# ATSAMA5D27CLD1G register map
Vendor: Microchip Technology; Series: SAMA5D2; File version: 0
Registers are 32-bit, read-write, reset 0x0 unless marked. A register's access mark holds for its fields unless they carry their own. Offsets are from the block's base; [hi:lo] are bit positions; {n}, {i} and the like mark numbered series.

## SFC — Secure Fuse Controller
Base 0xF804C000; register names take the prefix SFC_
0x00 KR wo — SFC Key Register
  [7:0] KEY — Key Code
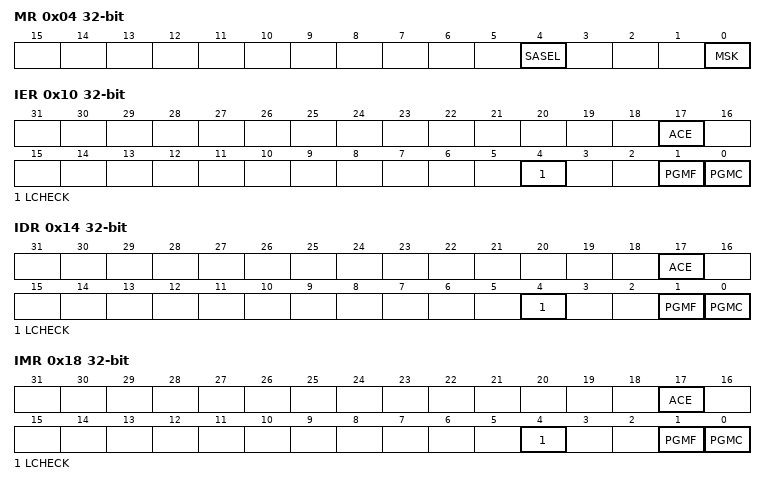
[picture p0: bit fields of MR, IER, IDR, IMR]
0x04 MR — SFC Mode Register
  [4] SASEL — Sense Amplifier Selection
  [0] MSK — Mask Data Registers
0x10 IER wo — SFC Interrupt Enable Register
  [17] ACE — Area Check Error Interrupt Enable
  [4] LCHECK — Live Integrity Check Error Interrupt Enable
  [1] PGMF — Programming Sequence Failed Interrupt Enable
  [0] PGMC — Programming Sequence Completed Interrupt Enable
0x14 IDR wo — SFC Interrupt Disable Register
  [17] ACE — Area Check Error Interrupt Disable
  [4] LCHECK — Live Integrity Check Error Interrupt Disable
  [1] PGMF — Programming Sequence Failed Interrupt Disable
  [0] PGMC — Programming Sequence Completed Interrupt Disable
0x18 IMR ro — SFC Interrupt Mask Register
  [17] ACE — Area Check Error Interrupt Mask
  [4] LCHECK — Live Integrity Checking Error Interrupt Mask
  [1] PGMF — Programming Sequence Failed Interrupt Mask
  [0] PGMC — Programming Sequence Completed Interrupt Mask
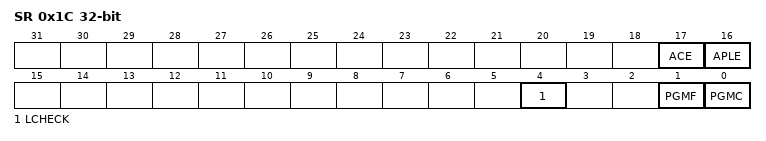
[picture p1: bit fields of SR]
0x1C SR ro — SFC Status Register
  [17] ACE — Area Check Error (cleared on read)
  [16] APLE — Area Programming Lock Error (cleared on read)
  [4] LCHECK — Live Integrity Checking Error (cleared on read)
  [1] PGMF — Programming Sequence Failed (cleared on read)
  [0] PGMC — Programming Sequence Completed (cleared on read)
{0x20+4i} DR[{i}] (i=0..16) — SFC Data Register
  [31:0] DATA — Fuse Data

## SFR — Special Function Registers
Base 0xF8030000; register names take the prefix SFR_
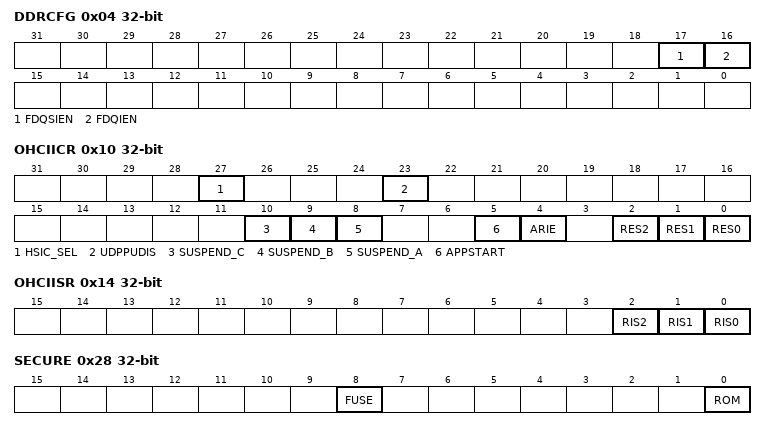
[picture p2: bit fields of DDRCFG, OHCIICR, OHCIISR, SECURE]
0x04 DDRCFG — DDR Configuration Register
  [17] FDQSIEN — Force DDR_DQS Input Buffer Always On
  [16] FDQIEN — Force DDR_DQ Input Buffer Always On
0x10 OHCIICR — OHCI Interrupt Configuration Register
  [27] HSIC_SEL
  [23] UDPPUDIS — USB DEVICE PULLUP DISABLE
  [10] SUSPEND_C — USB PORT C
  [9] SUSPEND_B — USB PORT B
  [8] SUSPEND_A — USB PORT A
  [5] APPSTART
  [4] ARIE — OHCI Asynchronous Resume Interrupt Enable
  [2] RES2 — USB PORTx RESET
  [1] RES1 — USB PORTx RESET
  [0] RES0 — USB PORTx RESET
0x14 OHCIISR ro — OHCI Interrupt Status Register
  [2] RIS2 — OHCI Resume Interrupt Status Port 2
  [1] RIS1 — OHCI Resume Interrupt Status Port 1
  [0] RIS0 — OHCI Resume Interrupt Status Port 0
0x28 SECURE — Security Configuration Register
  [8] FUSE — Disable Access to Fuse Controller
  [0] ROM — Disable Access to ROM Code
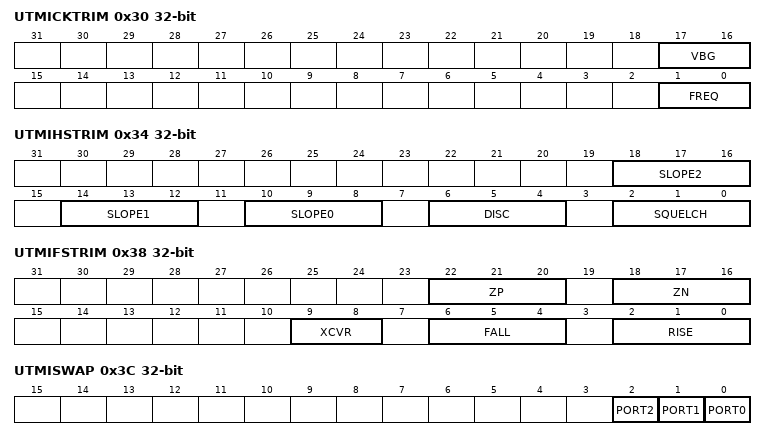
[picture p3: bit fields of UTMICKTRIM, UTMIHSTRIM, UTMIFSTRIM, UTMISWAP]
0x30 UTMICKTRIM — UTMI Clock Trimming Register
  [17:16] VBG — UTMI Band Gap Voltage Trimming
  [1:0] FREQ — UTMI Reference Clock Frequency
    0=12 MHz reference clock; 1=16 MHz reference clock; 2=24 MHz reference clock
0x34 UTMIHSTRIM — UTMI High-Speed Trimming Register
  [18:16] SLOPE2 — UTMI HS PORTx Transceiver Slope Trimming
  [14:12] SLOPE1 — UTMI HS PORTx Transceiver Slope Trimming
  [10:8] SLOPE0 — UTMI HS PORTx Transceiver Slope Trimming
  [6:4] DISC — UTMI Disconnect Voltage Trimming
  [2:0] SQUELCH — UTMI HS SQUELCH Voltage Trimming
0x38 UTMIFSTRIM — UTMI Full-Speed Trimming Register
  [22:20] ZP — FS Transceiver PMOS Impedance Trimming
  [18:16] ZN — FS Transceiver NMOS Impedance Trimming
  [9:8] XCVR — FS Transceiver Crossover Voltage Trimming
  [6:4] FALL — FS Transceiver Output Falling Slope Trimming
  [2:0] RISE — FS Transceiver Output Rising Slope Trimming
0x3C UTMISWAP — UTMI DP/DM Pin Swapping Register
  [all] fields
    0=NORMAL (DP/DM normal pinout.); 1=SWAPPED (DP/DM swapped pinout.)
  [2] PORT2 — PORT 2 DP/DM Pin Swapping
  [1] PORT1 — PORT 1 DP/DM Pin Swapping
  [0] PORT0 — PORT 0 DP/DM Pin Swapping
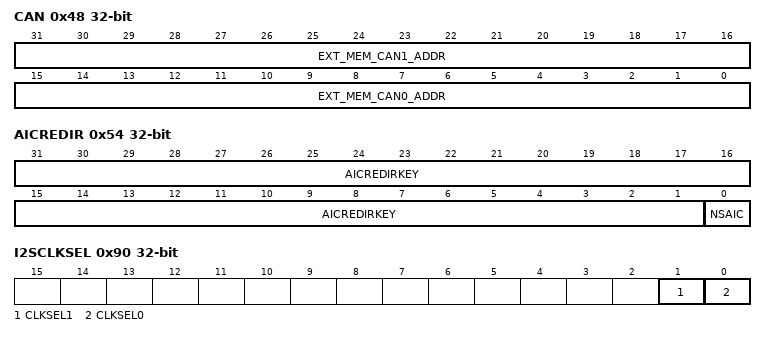
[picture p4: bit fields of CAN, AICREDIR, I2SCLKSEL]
0x48 CAN — CAN Memories Address-based Register
  [31:16] EXT_MEM_CAN1_ADDR — MSB CAN1 DMA Base Address
  [15:0] EXT_MEM_CAN0_ADDR — MSB CAN0 DMA Base Address
0x4C SN0 ro — Serial Number 0 Register
  [31:0] SN0 — Serial Number 0
0x50 SN1 ro — Serial Number 1 Register
  [31:0] SN1 — Serial Number 1
0x54 AICREDIR — AIC Interrupt Redirection Register
  [31:1] AICREDIRKEY — Unlock Key
  [0] NSAIC — Interrupt Redirection to Non-Secure AIC
0x58 L2CC_HRAMC — L2CC_HRAMC1
  [0] SRAM_SEL — SRAM Selector
0x90 I2SCLKSEL — I2SC Register
  [1] CLKSEL1 — Clock Selection 1
  [0] CLKSEL0 — Clock Selection 0
0x94 QSPICLK_REG — QSPI Clock Pad Supply Select Register
  [0] SUP_SEL — Supply Selection
